# MKW36Z4 register map
Vendor: NXP Semiconductors; Series: Kinetis_W; File version: 1.6
CPU: CM0PLUS r0p0, little endian, no MPU, no FPU, VTOR, 2 interrupt priority bits
Registers are 16-bit, read-write, no defined reset value unless marked. A register's access mark holds for its fields unless they carry their own. Offsets are from the block's base; [hi:lo] are bit positions; 'fields as' and 'values as' point back to an identical list.

## FTFE_FlashConfig — Flash configuration field
Base 0x00000400; register names take the prefix NV_
0x00 BACKKEY3 8-bit ro reset 0xFF — Backdoor Comparison Key 3.
  [7:0] KEY — Backdoor Comparison Key.
0x01 BACKKEY2 8-bit ro reset 0xFF — Backdoor Comparison Key 2.
  [7:0] KEY — Backdoor Comparison Key.
0x02 BACKKEY1 8-bit ro reset 0xFF — Backdoor Comparison Key 1.
  [7:0] KEY — Backdoor Comparison Key.
0x03 BACKKEY0 8-bit ro reset 0xFF — Backdoor Comparison Key 0.
  [7:0] KEY — Backdoor Comparison Key.
0x04 BACKKEY7 8-bit ro reset 0xFF — Backdoor Comparison Key 7.
  [7:0] KEY — Backdoor Comparison Key.
0x05 BACKKEY6 8-bit ro reset 0xFF — Backdoor Comparison Key 6.
  [7:0] KEY — Backdoor Comparison Key.
0x06 BACKKEY5 8-bit ro reset 0xFF — Backdoor Comparison Key 5.
  [7:0] KEY — Backdoor Comparison Key.
0x07 BACKKEY4 8-bit ro reset 0xFF — Backdoor Comparison Key 4.
  [7:0] KEY — Backdoor Comparison Key.
0x08 FPROT3 8-bit ro reset 0xFF — Non-volatile P-Flash Protection 1 - Low Register
  [7:0] PROT — P-Flash Region Protect
0x09 FPROT2 8-bit ro reset 0xFF — Non-volatile P-Flash Protection 1 - High Register
  [7:0] PROT — P-Flash Region Protect
0x0A FPROT1 8-bit ro reset 0xFF — Non-volatile P-Flash Protection 0 - Low Register
  [7:0] PROT — P-Flash Region Protect
0x0B FPROT0 8-bit ro reset 0xFF — Non-volatile P-Flash Protection 0 - High Register
  [7:0] PROT — P-Flash Region Protect
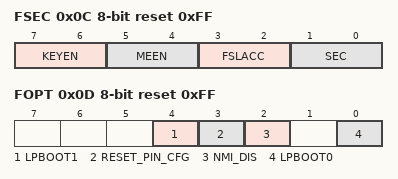
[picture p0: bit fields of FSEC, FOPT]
0x0C FSEC 8-bit ro reset 0xFF — Non-volatile Flash Security Register
  [7:6] KEYEN — Backdoor Key Security Enable
    2=Backdoor key access enabled; 3=Backdoor key access disabled
  [5:4] MEEN
    2=Mass erase is disabled; 3=Mass erase is enabled
  [3:2] FSLACC — Freescale Failure Analysis Access Code
    2=Freescale factory access denied; 3=Freescale factory access granted
  [1:0] SEC — Flash Security
    2=MCU security status is unsecure; 3=MCU security status is secure
0x0D FOPT 8-bit ro reset 0xFF — Non-volatile Flash Option Register
  [4] LPBOOT1
    0=Core and system clock divider (OUTDIV1) is 0x7 (divide by 8) when LPBOOT0=0 or 0x3 (divide by 4) when LPBOOT0=1; 1=Core and system clock divider (OUTDIV1) is 0x1 (divide by 2) when LPBOOT0=0 or 0x0 (divide by 1) when LPBOOT0=1
  [3] RESET_PIN_CFG
    0=RESET pin is disabled following a POR and cannot be enabled as reset function; 1=RESET_b pin is dedicated
  [2] NMI_DIS
    0=NMI interrupts are always blocked; 1=NMI_b pin/interrupts reset default to enabled
  [0] LPBOOT0
    0=Core and system clock divider (OUTDIV1) is 0x7 (divide by 8) when LPBOOT1=0 or 0x1 (divide by 2) when LPBOOT1=1; 1=Core and system clock divider (OUTDIV1) is 0x3 (divide by 4) when LPBOOT1=0 or 0x0 (divide by 1) when LPBOOT1=1
0x0E FEPROT 8-bit ro reset 0xFF — Non-volatile EERAM Protection Register
  [7:0] EPROT
0x0F FDPROT 8-bit ro reset 0xFF — Non-volatile D-Flash Protection Register
  [7:0] DPROT — D-Flash Region Protect

## DMAMUX0 — DMAMUX
Base 0x40021000
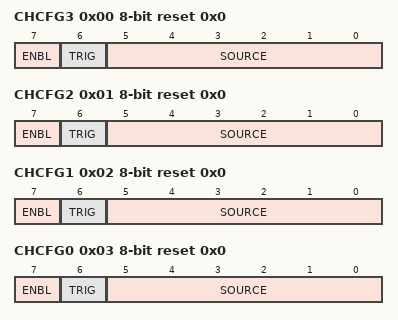
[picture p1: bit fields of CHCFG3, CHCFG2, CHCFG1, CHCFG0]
0x00 CHCFG3 8-bit reset 0x0 — Channel Configuration register
  [7] ENBL — DMA Channel Enable
    0=DMA channel is disabled. This mode is primarily used during configuration of the DMAMux. The DMA has separate channel enables/disables, which should be used to disable or reconfigure a DMA channel.; 1=DMA channel is enabled
  [6] TRIG — DMA Channel Trigger Enable
    0=Triggering is disabled. If triggering is disabled and ENBL is set, the DMA Channel will simply route the specified source to the DMA channel. (Normal mode); 1=Triggering is enabled. If triggering is enabled and ENBL is set, the DMAMUX is in Periodic Trigger mode.
  [5:0] SOURCE — DMA Channel Source (Slot)
0x01 CHCFG2 8-bit reset 0x0 — Channel Configuration register
  fields as CHCFG3
0x02 CHCFG1 8-bit reset 0x0 — Channel Configuration register
  fields as CHCFG3
0x03 CHCFG0 8-bit reset 0x0 — Channel Configuration register
  fields as CHCFG3
